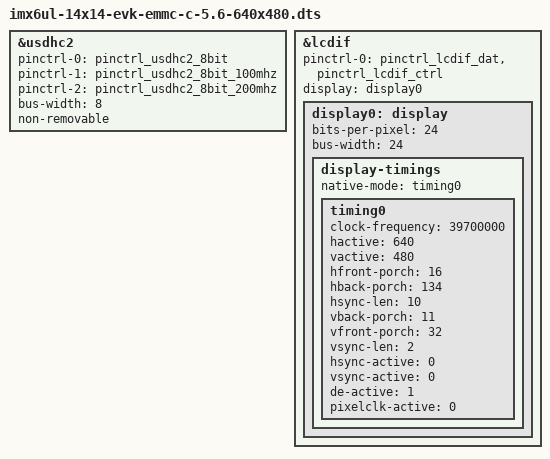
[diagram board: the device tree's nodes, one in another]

/*
 * Copyright (C) 2016 Freescale Semiconductor, Inc.
 *
 * This program is free software; you can redistribute it and/or modify
 * it under the terms of the GNU General Public License version 2 as
 * published by the Free Software Foundation.
 */

#include "imx6ul-14x14-evk.dts"

&usdhc2 {
	pinctrl-names = "default", "state_100mhz", "state_200mhz";
	pinctrl-0 = <&pinctrl_usdhc2_8bit>;
	pinctrl-1 = <&pinctrl_usdhc2_8bit_100mhz>;
	pinctrl-2 = <&pinctrl_usdhc2_8bit_200mhz>;
	bus-width = <8>;
	non-removable;
	status = "okay";
};
&lcdif {
	pinctrl-names = "default";
	pinctrl-0 = <&pinctrl_lcdif_dat
		     &pinctrl_lcdif_ctrl>;
	display = <&display0>;
	status = "okay";

	display0: display {
		bits-per-pixel = <24>;
		bus-width = <24>;

		display-timings {
			native-mode = <&timing0>;
			timing0: timing0 {
			clock-frequency = <39700000>;
			hactive = <640>;
			vactive = <480>;
			hfront-porch = <16>;
			hback-porch = <134>;
			hsync-len = <10>;
			vback-porch = <11>;
			vfront-porch = <32>;
			vsync-len = <2>;

			hsync-active = <0>;
			vsync-active = <0>;
			de-active = <1>;
			pixelclk-active = <0>;
			};
		};
	};
};
